AUTOSAR XML (schema 321)
package /ComponentType
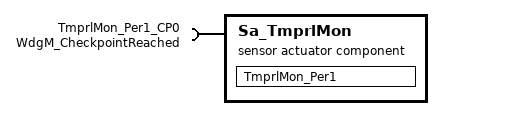
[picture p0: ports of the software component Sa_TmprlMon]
  sensor actuator software component type Sa_TmprlMon
    require port TmprlMon_Per1_CP0: client-com-spec=CheckpointReached, required-interface=WdgM_CheckpointReached
  internal behavior Sa_TmprlMon_InternalBehavior: component=Sa_TmprlMon, port-api-option{enable-take-address=false, indirect-api=false, port=TmprlMon_Per1_CP0}
    runnable TmprlMon_Per1
      sync call SC_TmprlMon_Per1_CP0_CheckpointReached: operation=TmprlMon_Per1_CP0.CheckpointReached, timeout=0
  swc implementation Sa_TmprlMon_Implementation: behavior=Sa_TmprlMon_InternalBehavior
    code-descriptors:
      code Code: type=SRC
package /PortInterface
  client server interface WdgM_CheckpointReached: is-service=true
    operation CheckpointReached: possible-error=E_NOT_OK  # Indicates to the Watchdog Manager that a Checkpoint within a Supervised Entity has been reached.
    error E_NOT_OK: error-code=1
